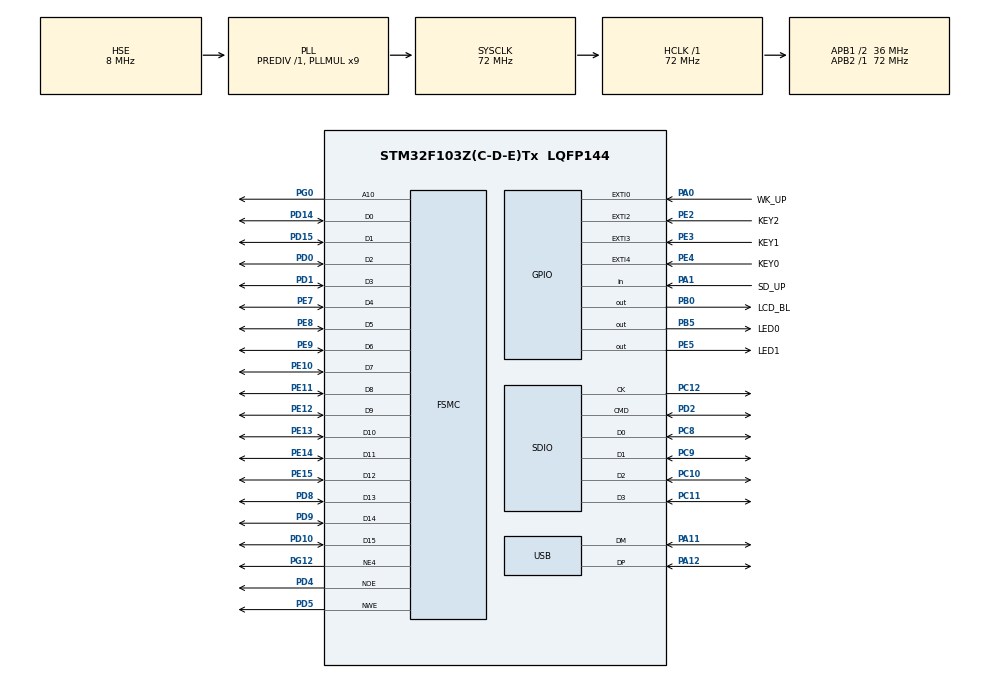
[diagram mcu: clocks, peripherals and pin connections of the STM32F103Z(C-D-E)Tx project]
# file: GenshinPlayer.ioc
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Mcu.Family=STM32F1
FSMC.AddressSetupTime1=0
USB_DEVICE.CLASS_NAME_FS=HID
SH.FSMC_D1_DA1.0=FSMC_D1,16b-d1
FATFS._USE_LFN=3
FATFS0.BSP.api=Unknown
VP_FATFS_VS_SDIO.Mode=SDIO
PC10.Signal=SDIO_D2
PC12.Signal=SDIO_CK
SH.FSMC_NWE.0=FSMC_NWE,Lcd1
PG0.Signal=FSMC_A10
SH.FSMC_D0_DA0.0=FSMC_D0,16b-d1
PA11.Mode=Device
PB0.GPIO_Label=LCD_BL
FSMC.ExtendedBusTurnAroundDuration1=0
RCC.SYSCLKSource=RCC_SYSCLKSOURCE_PLLCLK
ProjectManager.StackSize=0x400
PA12.Signal=USB_DP
PB0.PinState=GPIO_PIN_SET
RCC.HCLKFreq_Value=72000000
PD4.Signal=FSMC_NOE
RCC.APB2TimFreq_Value=72000000
PD0.Signal=FSMC_D2_DA2
PD8.Signal=FSMC_D13_DA13
PE5.Signal=GPIO_Output
OSC_OUT.Mode=HSE-External-Oscillator
SH.FSMC_A10.0=FSMC_A10,A10_1
OSC_OUT.Signal=RCC_OSC_OUT
RCC.AHBFreq_Value=72000000
FATFS0.BSP.ip=GPIO
PB3.Mode=JTAG_4_pins
FATFS0.BSP.i2caddr=0
PA15.Mode=JTAG_4_pins
RCC.PLLMUL=RCC_PLL_MUL9
PE13.Signal=FSMC_D10_DA10
SH.FSMC_D14_DA14.0=FSMC_D14,16b-d1
SH.FSMC_D10_DA10.0=FSMC_D10,16b-d1
PC14-OSC32_IN.Mode=LSE-External-Oscillator
PE9.Signal=FSMC_D6_DA6
PA14.Mode=JTAG_4_pins
SH.FSMC_D6_DA6.0=FSMC_D6,16b-d1
PE4.GPIO_Label=KEY0
PC9.Mode=SD_4_bits_Wide_bus
PE2.Signal=GPXTI2
FSMC.BusTurnAroundDuration1=0
PE10.Signal=FSMC_D7_DA7
PE4.Signal=GPXTI4
SH.FSMC_D5_DA5.0=FSMC_D5,16b-d1
SH.FSMC_D4_DA4.0=FSMC_D4,16b-d1
Mcu.Package=LQFP144
FATFS0.BSP.solution=PA1
SH.FSMC_D13_DA13.0=FSMC_D13,16b-d1
PA15.Signal=SYS_JTDI
PC11.Mode=SD_4_bits_Wide_bus
PB5.GPIO_Label=LED0
SH.FSMC_D3_DA3.0=FSMC_D3,16b-d1
RCC.APB1TimFreq_Value=72000000
SH.FSMC_D2_DA2.0=FSMC_D2,16b-d1
PE7.Signal=FSMC_D4_DA4
PE2.GPIO_Label=KEY2
PD15.Signal=FSMC_D1_DA1
PG12.Signal=FSMC_NE4
PE3.GPIO_ModeDefaultEXTI=GPIO_MODE_IT_FALLING
PB5.GPIO_ModeDefaultOutputPP=GPIO_MODE_OUTPUT_OD
FSMC.ExtendedAddressSetupTime1=0
PC15-OSC32_OUT.Mode=LSE-External-Oscillator
FATFS0.BSP.STBoard=false
SH.FSMC_D12_DA12.0=FSMC_D12,16b-d1
USB_DEVICE.VirtualModeFS=Hid_FS
FSMC.ExtendedMode1=FSMC_EXTENDED_MODE_ENABLE
PC11.Signal=SDIO_D3
FATFS0.BSP.mode=Input
PC8.Signal=SDIO_D0
PC10.Mode=SD_4_bits_Wide_bus
PE4.GPIO_ModeDefaultEXTI=GPIO_MODE_IT_FALLING
RCC.USBPrescaler=RCC_USBCLKSOURCE_PLL_DIV1_5
PD1.Signal=FSMC_D3_DA3
SH.FSMC_D9_DA9.0=FSMC_D9,16b-d1
PD9.Signal=FSMC_D14_DA14
PD5.Signal=FSMC_NWE
RCC.APB1CLKDivider=RCC_HCLK_DIV2
PC14-OSC32_IN.Signal=RCC_OSC32_IN
PA0-WKUP.GPIO_ModeDefaultEXTI=GPIO_MODE_IT_RISING
PA0-WKUP.GPIO_Label=WK_UP
PA0-WKUP.Signal=GPXTI0
SH.FSMC_D8_DA8.0=FSMC_D8,16b-d1
FATFS0.BSP.instance=PA1
PD10.Signal=FSMC_D15_DA15
PA13.Signal=SYS_JTMS-SWDIO
ProjectManager.TargetToolchain=MDK-ARM V5.27
FSMC.DataSetupTime1=5
FATFS._CODE_PAGE=936
OSC_IN.Signal=RCC_OSC_IN
RCC.USBFreq_Value=48000000
SDIO.ClockDiv=4
PE11.Signal=FSMC_D8_DA8
PC15-OSC32_OUT.Signal=RCC_OSC32_OUT
PA1.Signal=GPIO_Input
PD2.Mode=SD_4_bits_Wide_bus
FATFS.BSP.number=1
PE2.GPIO_PuPd=GPIO_PULLUP
PC12.Mode=SD_4_bits_Wide_bus
SH.FSMC_D7_DA7.0=FSMC_D7,16b-d1
FSMC.ExtendedDataSetupTime1=3
board=custom
PG12.Mode=NorPsramChipSelect4_1
VP_USB_DEVICE_VS_USB_DEVICE_HID_FS.Mode=HID_FS
RCC.APB2Freq_Value=72000000
PE14.Signal=FSMC_D11_DA11
PE15.Signal=FSMC_D12_DA12
PE8.Signal=FSMC_D5_DA5
NVIC.USB_LP_CAN1_RX0_IRQn=true\:5\:0\:true\:false\:true\:false\:true
PA1.GPIO_Label=SD_UP
PE3.GPIO_PuPd=GPIO_PULLUP
PA13.Mode=JTAG_4_pins
Mcu.Name=STM32F103Z(C-D-E)Tx
PE12.Signal=FSMC_D9_DA9
PE4.GPIO_PuPd=GPIO_PULLUP
PD14.Signal=FSMC_D0_DA0
PC8.Mode=SD_4_bits_Wide_bus
PB3.Signal=SYS_JTDO-TRACESWO
RCC.SYSCLKFreq_VALUE=72000000
PB5.Signal=GPIO_Output
PA12.Mode=Device
OSC_IN.Mode=HSE-External-Oscillator
PE5.GPIO_Label=LED1
PA11.Signal=USB_DM
SH.FSMC_D15_DA15.0=FSMC_D15,16b-d1
PA14.Signal=SYS_JTCK-SWCLK
ProjectManager.HeapSize=0x200
PE5.GPIO_ModeDefaultOutputPP=GPIO_MODE_OUTPUT_OD
SH.FSMC_D11_DA11.0=FSMC_D11,16b-d1
SH.FSMC_NOE.0=FSMC_NOE,Lcd1
NVIC.PriorityGroup=NVIC_PRIORITYGROUP_4
PE3.Signal=GPXTI3
PE3.GPIO_Label=KEY1
PA0-WKUP.GPIO_PuPd=GPIO_PULLDOWN
PE2.GPIO_ModeDefaultEXTI=GPIO_MODE_IT_FALLING
PC9.Signal=SDIO_D1
PD2.Signal=SDIO_CMD
RCC.APB1Freq_Value=36000000
PB0.Signal=GPIO_Output
USB_DEVICE.VirtualMode=Hid
FATFS0.BSP.name=Detect_SDIO

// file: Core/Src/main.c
/* USER CODE BEGIN Header */
/*********doc**********
keyboard hid config doc: https://zhuanlan.zhihu.com/p/87634147
hid doc: https://docs.microsoft.com/zh-cn/windows-hardware/drivers/hid/
hid code list: https://blog.csdn.net/bona020/article/details/101289147

*******************/
/**
  ******************************************************************************
  * @file           : main.c
  * @brief          : Main program body
  ******************************************************************************
  * @attention
  *
  * <h2><center>&copy; Copyright (c) 2022 STMicroelectronics.
  * All rights reserved.</center></h2>
  *
  * This software component is licensed by ST under Ultimate Liberty license
  * SLA0044, the "License"; You may not use this file except in compliance with
  * the License. You may obtain a copy of the License at:
  *                             www.st.com/SLA0044
  *
  ******************************************************************************
  */
/* USER CODE END Header */
#include "main.h"
#include "fatfs.h"
#include "sdio.h"
#include "usb_device.h"
#include "gpio.h"
#include "fsmc.h"

/* USER CODE BEGIN Includes */
#include "genshin_player.h"
/* USER CODE END Includes */

void SystemClock_Config(void);

int main(void)
{

  /* MCU Configuration--------------------------------------------------------*/

  /* Reset of all peripherals, Initializes the Flash interface and the Systick. */
  HAL_Init();

  /* Configure the system clock */
  SystemClock_Config();

  /* Initialize all configured peripherals */
  MX_GPIO_Init();
  MX_FSMC_Init();
  MX_SDIO_SD_Init();
  MX_USB_DEVICE_Init();
  MX_FATFS_Init();
  /* USER CODE BEGIN 2 */
	genshin_setup();
  /* USER CODE END 2 */

  /* Infinite loop */
  /* USER CODE BEGIN WHILE */
  while (1)
  {
		genshin_loop();
    /* USER CODE END WHILE */

  }
}

void SystemClock_Config(void)
{
  RCC_OscInitTypeDef RCC_OscInitStruct = {0};
  RCC_ClkInitTypeDef RCC_ClkInitStruct = {0};
  RCC_PeriphCLKInitTypeDef PeriphClkInit = {0};

  /** Initializes the RCC Oscillators according to the specified parameters
  * in the RCC_OscInitTypeDef structure.
  */
  RCC_OscInitStruct.OscillatorType = RCC_OSCILLATORTYPE_HSE;
  RCC_OscInitStruct.HSEState = RCC_HSE_ON;
  RCC_OscInitStruct.HSEPredivValue = RCC_HSE_PREDIV_DIV1;
  RCC_OscInitStruct.HSIState = RCC_HSI_ON;
  RCC_OscInitStruct.PLL.PLLState = RCC_PLL_ON;
  RCC_OscInitStruct.PLL.PLLSource = RCC_PLLSOURCE_HSE;
  RCC_OscInitStruct.PLL.PLLMUL = RCC_PLL_MUL9;
  if (HAL_RCC_OscConfig(&RCC_OscInitStruct) != HAL_OK)
  {
    Error_Handler();
  }
  /** Initializes the CPU, AHB and APB buses clocks
  */
  RCC_ClkInitStruct.ClockType = RCC_CLOCKTYPE_HCLK|RCC_CLOCKTYPE_SYSCLK
                              |RCC_CLOCKTYPE_PCLK1|RCC_CLOCKTYPE_PCLK2;
  RCC_ClkInitStruct.SYSCLKSource = RCC_SYSCLKSOURCE_PLLCLK;
  RCC_ClkInitStruct.AHBCLKDivider = RCC_SYSCLK_DIV1;
  RCC_ClkInitStruct.APB1CLKDivider = RCC_HCLK_DIV2;
  RCC_ClkInitStruct.APB2CLKDivider = RCC_HCLK_DIV1;

  if (HAL_RCC_ClockConfig(&RCC_ClkInitStruct, FLASH_LATENCY_2) != HAL_OK)
  {
    Error_Handler();
  }
  PeriphClkInit.PeriphClockSelection = RCC_PERIPHCLK_USB;
  PeriphClkInit.UsbClockSelection = RCC_USBCLKSOURCE_PLL_DIV1_5;
  if (HAL_RCCEx_PeriphCLKConfig(&PeriphClkInit) != HAL_OK)
  {
    Error_Handler();
  }
}

void Error_Handler(void)
{
}

/************************ (C) COPYRIGHT STMicroelectronics *****END OF FILE****/
